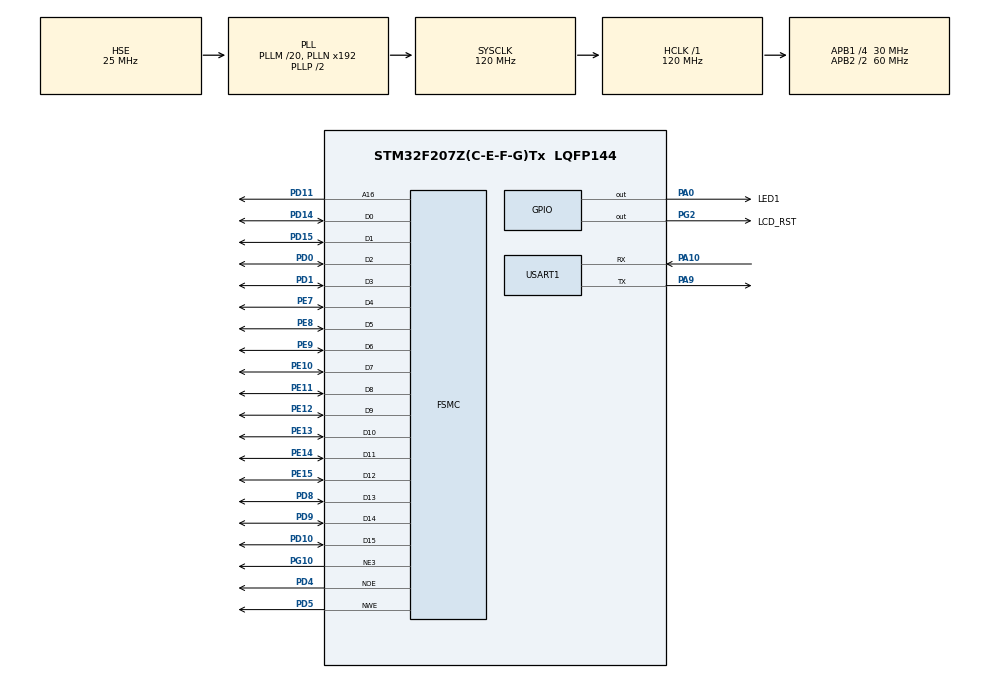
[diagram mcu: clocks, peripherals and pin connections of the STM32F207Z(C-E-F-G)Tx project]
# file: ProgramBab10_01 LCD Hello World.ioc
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FSMC.AddressSetupTime1=5
FSMC.DataSetupTime1=5
Mcu.Family=STM32F2
Mcu.Name=STM32F207Z(C-E-F-G)Tx
Mcu.Package=LQFP144
NVIC.PriorityGroup=NVIC_PRIORITYGROUP_4
PA0-WKUP.GPIO_Label=LED1
PA0-WKUP.Signal=GPIO_Output
PA10.Mode=Asynchronous
PA10.Signal=USART1_RX
PA9.Mode=Asynchronous
PA9.Signal=USART1_TX
PD0.Signal=FSMC_D2_DA2
PD1.Signal=FSMC_D3_DA3
PD10.Signal=FSMC_D15_DA15
PD11.Signal=FSMC_A16_CLE
PD14.Signal=FSMC_D0_DA0
PD15.Signal=FSMC_D1_DA1
PD4.Signal=FSMC_NOE
PD5.Signal=FSMC_NWE
PD8.Signal=FSMC_D13_DA13
PD9.Signal=FSMC_D14_DA14
PE10.Signal=FSMC_D7_DA7
PE11.Signal=FSMC_D8_DA8
PE12.Signal=FSMC_D9_DA9
PE13.Signal=FSMC_D10_DA10
PE14.Signal=FSMC_D11_DA11
PE15.Signal=FSMC_D12_DA12
PE7.Signal=FSMC_D4_DA4
PE8.Signal=FSMC_D5_DA5
PE9.Signal=FSMC_D6_DA6
PG10.Mode=NorPsramChipSelect3_1
PG10.Signal=FSMC_NE3
PG2.GPIO_Label=LCD_RST
PG2.Signal=GPIO_Output
PH0-OSC_IN.Mode=HSE-External-Oscillator
PH0-OSC_IN.Signal=RCC_OSC_IN
PH1-OSC_OUT.Mode=HSE-External-Oscillator
PH1-OSC_OUT.Signal=RCC_OSC_OUT
ProjectManager.HeapSize=0x200
ProjectManager.StackSize=0x400
ProjectManager.TargetToolchain=STM32CubeIDE
RCC.48MHZClocksFreq_Value=60000000
RCC.AHBFreq_Value=120000000
RCC.APB1CLKDivider=RCC_HCLK_DIV4
RCC.APB1Freq_Value=30000000
RCC.APB1TimFreq_Value=60000000
RCC.APB2CLKDivider=RCC_HCLK_DIV2
RCC.APB2Freq_Value=60000000
RCC.APB2TimFreq_Value=120000000
RCC.CortexFreq_Value=120000000
RCC.HCLKFreq_Value=120000000
RCC.HSE_VALUE=25000000
RCC.HSI_VALUE=16000000
RCC.LSE_VALUE=32768
RCC.PLLM=20
RCC.PLLSourceVirtual=RCC_PLLSOURCE_HSE
RCC.SYSCLKFreq_VALUE=120000000
RCC.SYSCLKSource=RCC_SYSCLKSOURCE_PLLCLK
RCC.VCOOutputFreq_Value=240000000
SH.FSMC_A16_CLE.0=FSMC_A16,A16_1
SH.FSMC_D0_DA0.0=FSMC_D0,16b-d1
SH.FSMC_D10_DA10.0=FSMC_D10,16b-d1
SH.FSMC_D11_DA11.0=FSMC_D11,16b-d1
SH.FSMC_D12_DA12.0=FSMC_D12,16b-d1
SH.FSMC_D13_DA13.0=FSMC_D13,16b-d1
SH.FSMC_D14_DA14.0=FSMC_D14,16b-d1
SH.FSMC_D15_DA15.0=FSMC_D15,16b-d1
SH.FSMC_D1_DA1.0=FSMC_D1,16b-d1
SH.FSMC_D2_DA2.0=FSMC_D2,16b-d1
SH.FSMC_D3_DA3.0=FSMC_D3,16b-d1
SH.FSMC_D4_DA4.0=FSMC_D4,16b-d1
SH.FSMC_D5_DA5.0=FSMC_D5,16b-d1
SH.FSMC_D6_DA6.0=FSMC_D6,16b-d1
SH.FSMC_D7_DA7.0=FSMC_D7,16b-d1
SH.FSMC_D8_DA8.0=FSMC_D8,16b-d1
SH.FSMC_D9_DA9.0=FSMC_D9,16b-d1
SH.FSMC_NOE.0=FSMC_NOE,Lcd1
SH.FSMC_NWE.0=FSMC_NWE,Lcd1
USART1.VirtualMode=VM_ASYNC
board=custom

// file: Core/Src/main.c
/* USER CODE BEGIN Header */
/**
  ******************************************************************************
  * @file           : main.c
  * @brief          : Main program body
  ******************************************************************************
  * @attention
  *
  * <h2><center>&copy; Copyright (c) 2019 STMicroelectronics.
  * All rights reserved.</center></h2>
  *
  * This software component is licensed by ST under BSD 3-Clause license,
  * the "License"; You may not use this file except in compliance with the
  * License. You may obtain a copy of the License at:
  *                        opensource.org/licenses/BSD-3-Clause
  *
  ******************************************************************************
  */
/* USER CODE END Header */
#include "main.h"
#include "usart.h"
#include "gpio.h"
#include "fsmc.h"

/* USER CODE BEGIN Includes */
#include "global.h"
/* USER CODE END Includes */

void SystemClock_Config(void);

int main(void)
{

  /* MCU Configuration--------------------------------------------------------*/

  /* Reset of all peripherals, Initializes the Flash interface and the Systick. */
  HAL_Init();

  /* Configure the system clock */
  SystemClock_Config();

  /* Initialize all configured peripherals */
  MX_GPIO_Init();
  MX_FSMC_Init();
  MX_USART1_UART_Init();
  /* USER CODE BEGIN 2 */
   if (BSP_LCD_Init()==LCD_OK){
	   BSP_LCD_Clear(LCD_COLOR_BLACK);
	   BSP_LCD_SetBackColor(LCD_COLOR_BLACK);
	   BSP_LCD_SetTextColor(LCD_COLOR_YELLOW);
	   BSP_LCD_DisplayStringAt(0, 0, (uint8_t*)"HELLO WORLD!", CENTER_MODE);
	   BSP_LCD_SetTextColor(LCD_COLOR_RED);
	   BSP_LCD_FillRect(60, 60, 200, 60);
	   BSP_LCD_SetTextColor(LCD_COLOR_WHITE);
	   BSP_LCD_FillRect(60, 120, 200, 60);
   }
  /* USER CODE END 2 */

  /* Infinite loop */
  while (1)
  {

  }
}

void SystemClock_Config(void)
{
  RCC_OscInitTypeDef RCC_OscInitStruct = {0};
  RCC_ClkInitTypeDef RCC_ClkInitStruct = {0};

  /** Initializes the RCC Oscillators according to the specified parameters
  * in the RCC_OscInitTypeDef structure.
  */
  RCC_OscInitStruct.OscillatorType = RCC_OSCILLATORTYPE_HSE;
  RCC_OscInitStruct.HSEState = RCC_HSE_ON;
  RCC_OscInitStruct.PLL.PLLState = RCC_PLL_ON;
  RCC_OscInitStruct.PLL.PLLSource = RCC_PLLSOURCE_HSE;
  RCC_OscInitStruct.PLL.PLLM = 20;
  RCC_OscInitStruct.PLL.PLLN = 192;
  RCC_OscInitStruct.PLL.PLLP = RCC_PLLP_DIV2;
  RCC_OscInitStruct.PLL.PLLQ = 4;
  if (HAL_RCC_OscConfig(&RCC_OscInitStruct) != HAL_OK)
  {
    Error_Handler();
  }
  /** Initializes the CPU, AHB and APB buses clocks
  */
  RCC_ClkInitStruct.ClockType = RCC_CLOCKTYPE_HCLK|RCC_CLOCKTYPE_SYSCLK
                              |RCC_CLOCKTYPE_PCLK1|RCC_CLOCKTYPE_PCLK2;
  RCC_ClkInitStruct.SYSCLKSource = RCC_SYSCLKSOURCE_PLLCLK;
  RCC_ClkInitStruct.AHBCLKDivider = RCC_SYSCLK_DIV1;
  RCC_ClkInitStruct.APB1CLKDivider = RCC_HCLK_DIV4;
  RCC_ClkInitStruct.APB2CLKDivider = RCC_HCLK_DIV2;

  if (HAL_RCC_ClockConfig(&RCC_ClkInitStruct, FLASH_LATENCY_3) != HAL_OK)
  {
    Error_Handler();
  }
}

void Error_Handler(void)
{
}

/************************ (C) COPYRIGHT STMicroelectronics *****END OF FILE****/
